# MAIN_SEC_MMR0_CFG2 register map
Vendor: Texas Instruments
Peripheral module from a debugger description file (folder am62P).
Registers are 32-bit, access per field, reset 0xAA unless marked. A register's access mark holds for its fields unless they carry their own. Offsets are as the file gives them; lines under a group give offsets from that group; [hi:lo] are bit positions; {n}, {i} and the like mark numbered series; 'fields as' and 'values as' point back to an identical list; <NAME> marks a mode.

## MAIN_SEC_MMR0_CFG2
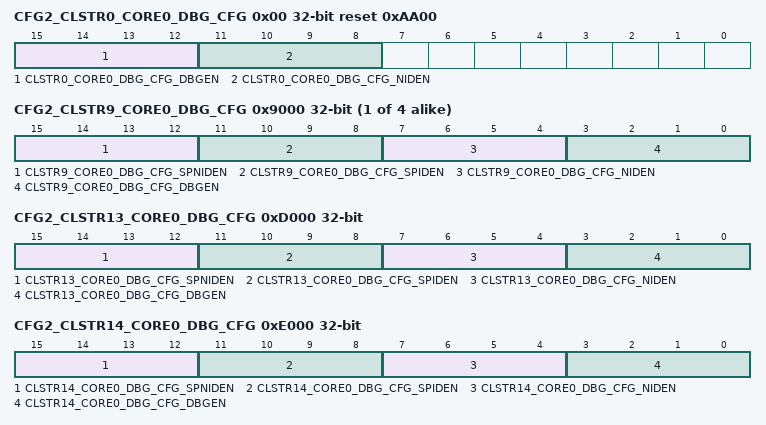
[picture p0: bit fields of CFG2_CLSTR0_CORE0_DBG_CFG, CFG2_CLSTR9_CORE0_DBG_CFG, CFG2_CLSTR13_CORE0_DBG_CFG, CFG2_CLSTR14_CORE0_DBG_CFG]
0x00 CFG2_CLSTR0_CORE0_DBG_CFG rw reset 0xAA00
  [15:12] CLSTR0_CORE0_DBG_CFG_DBGEN — Core0 Invasive debug activate. This is a fault tolerant bitfield that must be set 4'hA to activate 4'b1010 - Activated others - Deactivated
  [11:8] CLSTR0_CORE0_DBG_CFG_NIDEN — Core0 Non-invasive debug activate. This is a fault tolerant bitfield that must be set 4'hA to activate 4'b1010 - Activated others - Deactivated
{0x9000+0x40*i} CFG2_CLSTR9_CORE{i}_DBG_CFG (i=0..3)
  [15:12] CLSTR9_CORE{i}_DBG_CFG_SPNIDEN ro — Core{i} Secure Non-Invasive debug activate. This is a fault tolerant bitfield that must be set 4'hA to activate 4'b1010 - Activated others - Deactivated
  [11:8] CLSTR9_CORE{i}_DBG_CFG_SPIDEN ro — Core{i} Secure Invasive debug activate. This is a fault tolerant bitfield that must be set 4'hA to activate 4'b1010 - Activated others - Deactivated
  [7:4] CLSTR9_CORE{i}_DBG_CFG_NIDEN rw — Core{i} Non-Invasive debug activate. This is a fault tolerant bitfield that must be set 4'hA to activate 4'b1010 - Activated others - Deactivated
  [3:0] CLSTR9_CORE{i}_DBG_CFG_DBGEN rw — Core{i} Invasive debug activate. This is a fault tolerant bitfield that must be set 4'hA to activate 4'b1010 - Activated others - Deactivated
0xD000 CFG2_CLSTR13_CORE0_DBG_CFG
  [15:12] CLSTR13_CORE0_DBG_CFG_SPNIDEN ro — Core0 Secure Non-Invasive debug activate. This is a fault tolerant bitfield that must be set 4'hA to activate 4'b1010 - Activated others - Deactivated
  [11:8] CLSTR13_CORE0_DBG_CFG_SPIDEN ro — Core0 Secure Invasive debug activate. This is a fault tolerant bitfield that must be set 4'hA to activate 4'b1010 - Activated others - Deactivated
  [7:4] CLSTR13_CORE0_DBG_CFG_NIDEN rw — Core0 Non-Invasive debug activate. This is a fault tolerant bitfield that must be set 4'hA to activate 4'b1010 - Activated others - Deactivated
  [3:0] CLSTR13_CORE0_DBG_CFG_DBGEN rw — Core0 Invasive debug activate. This is a fault tolerant bitfield that must be set 4'hA to activate 4'b1010 - Activated others - Deactivated
0xE000 CFG2_CLSTR14_CORE0_DBG_CFG
  [15:12] CLSTR14_CORE0_DBG_CFG_SPNIDEN ro — Core0 Secure Non-Invasive debug activate. This is a fault tolerant bitfield that must be set 4'hA to activate 4'b1010 - Activated others - Deactivated
  [11:8] CLSTR14_CORE0_DBG_CFG_SPIDEN ro — Core0 Secure Invasive debug activate. This is a fault tolerant bitfield that must be set 4'hA to activate 4'b1010 - Activated others - Deactivated
  [7:4] CLSTR14_CORE0_DBG_CFG_NIDEN rw — Core0 Non-Invasive debug activate. This is a fault tolerant bitfield that must be set 4'hA to activate 4'b1010 - Activated others - Deactivated
  [3:0] CLSTR14_CORE0_DBG_CFG_DBGEN rw — Core0 Invasive debug activate. This is a fault tolerant bitfield that must be set 4'hA to activate 4'b1010 - Activated others - Deactivated
